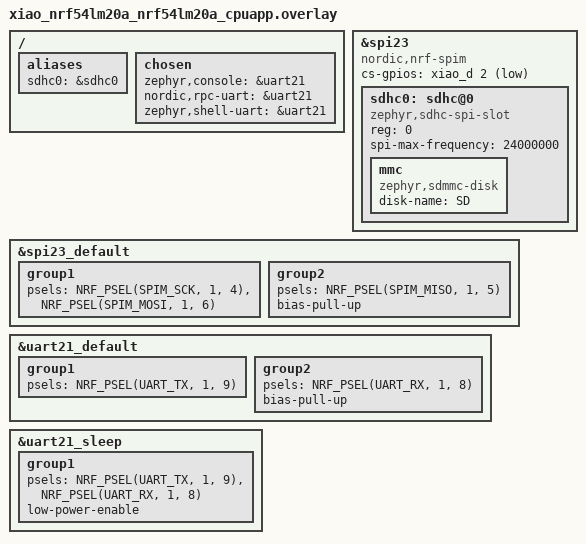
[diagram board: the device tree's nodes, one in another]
/*
 * SD Card configuration for XIAO nRF54LM20A with Expansion Base.
 *
 * Uses spi23 (XIAO SPI controller, low-speed SPIM domain) for SD card.
 *
 * On nRF54LM20A, the XIAO SPI header pins map to:
 *   D8 (SCK)  = P1.4    D9 (MISO) = P1.5    D10 (MOSI) = P1.6
 * These are routed through spi23, which is in the low-speed peripheral domain.
 *
 * No conflict with uart20 — spi23 and uart20 are independent instances.
 * Console remains on uart21 (TX=P1.9, RX=P1.8).
 */

/ {
	aliases {
		sdhc0 = &sdhc0;
	};

	chosen {
		zephyr,console = &uart21;
		nordic,rpc-uart = &uart21;
		zephyr,shell-uart = &uart21;
	};
};

&spi23 {
	compatible = "nordic,nrf-spim";
	status = "okay";

	cs-gpios = <&xiao_d 2 (GPIO_ACTIVE_LOW | GPIO_PULL_UP)>;
	sdhc0: sdhc@0 {
		compatible = "zephyr,sdhc-spi-slot";
		reg = <0>;
		status = "okay";
		mmc {
			compatible = "zephyr,sdmmc-disk";
			disk-name = "SD";
			status = "okay";
		};
		spi-max-frequency = <24000000>;
	};
};

/* Override spi23 pinctrl: add MISO pull-up as required by SD spec */
&spi23_default {
	group1 {
		psels = <NRF_PSEL(SPIM_SCK, 1, 4)>,
			<NRF_PSEL(SPIM_MOSI, 1, 6)>;
	};
	group2 {
		psels = <NRF_PSEL(SPIM_MISO, 1, 5)>;
		bias-pull-up;
	};
};

&uart21_default {
	group1 {
		psels = <NRF_PSEL(UART_TX, 1, 9)>;
	};

	group2 {
		psels = <NRF_PSEL(UART_RX, 1, 8)>;
		bias-pull-up;
	};
};

&uart21_sleep {
	group1 {
		psels = <NRF_PSEL(UART_TX, 1, 9)>,
			<NRF_PSEL(UART_RX, 1, 8)>;
		low-power-enable;
	};
};
